# ATmega328PB register map
Vendor: Atmel; File version: 1.0
CPU: other r0p0, little endian, no MPU, no FPU, 4 interrupt priority bits
Registers are 8-bit, read-write, reset 0x0 unless marked. A register's access mark holds for its fields unless they carry their own. Offsets are from the block's base; [hi:lo] are bit positions; {n}, {i} and the like mark numbered series; 'fields as' and 'values as' point back to an identical list.

## EXINT
Base 0x0000003B
0x00 PCIFR — Pin Change Interrupt Flag Register
  [3:0] PCIF — Pin Change Interrupt Flags
0x01 EIFR — External Interrupt Flag Register
  [1:0] INTF — External Interrupt Flags
0x02 EIMSK — External Interrupt Mask Register
  [1:0] INT — External Interrupt Request 1 Enable
0x2D PCICR — Pin Change Interrupt Control Register
  [3:0] PCIE — Pin Change Interrupt Enables
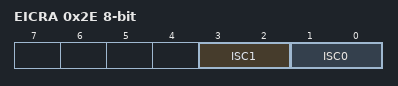
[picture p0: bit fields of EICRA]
0x2E EICRA — External Interrupt Control Register
  [3:2] ISC1 — External Interrupt Sense Control 1 Bits
    0=LOW_LEVEL_OF_INTX; 1=ANY_LOGICAL_CHANGE_OF_INTX; 2=FALLING_EDGE_OF_INTX; 3=RISING_EDGE_OF_INTX
  [1:0] ISC0 — External Interrupt Sense Control 0 Bits
    values as ISC1
0x30 PCMSK0 — Pin Change Mask Register 0
  [7:0] PCINT — Pin Change Enable Masks
0x31 PCMSK1 — Pin Change Mask Register 1
  [6:0] PCINT — Pin Change Enable Masks
0x32 PCMSK2 — Pin Change Mask Register 2
  [7:0] PCINT — Pin Change Enable Masks
0x38 PCMSK3 — Pin Change Mask Register 3
  [3:0] PCINT — Pin Change Enable Masks

## LOCKBIT — Lockbits
Base 0x00000000
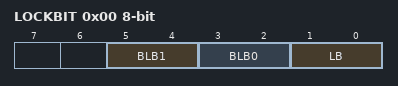
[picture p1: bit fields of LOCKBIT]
0x00 LOCKBIT
  [5:4] BLB1 — Boot Loader Protection Mode
    0=LPM_SPM_DISABLE (LPM and SPM prohibited in Boot Section); 1=LPM_DISABLE (LPM prohibited in Boot Section); 2=SPM_DISABLE (SPM prohibited in Boot Section); 3=NO_LOCK (No lock on SPM and LPM in Boot Section)
  [3:2] BLB0 — Boot Loader Protection Mode
    0=LPM_SPM_DISABLE (LPM and SPM prohibited in Application Section); 1=LPM_DISABLE (LPM prohibited in Application Section); 2=SPM_DISABLE (SPM prohibited in Application Section); 3=NO_LOCK (No lock on SPM and LPM in Application Section)
  [1:0] LB — Memory Lock
    0=PROG_VER_DISABLED (Further programming and verification disabled); 2=PROG_DISABLED (Further programming disabled); 3=NO_LOCK (No memory lock features enabled)

## PORTB — I/O Port
Base 0x00000023
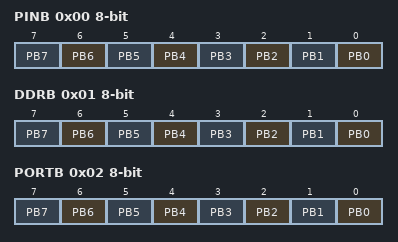
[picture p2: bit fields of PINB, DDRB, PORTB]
0x00 PINB — Port B Input Pins
  [n] PB{n} (n=0..7) — Pin B{n}
0x01 DDRB — Port B Data Direction Register
  [n] PB{n} (n=0..7) — Pin B{n}
0x02 PORTB — Port B Data Register
  [n] PB{n} (n=0..7) — Pin B{n}

## PORTC — I/O Port
Base 0x00000026
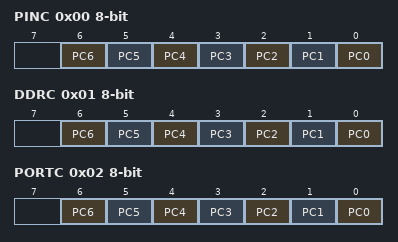
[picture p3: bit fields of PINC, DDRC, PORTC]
0x00 PINC — Port C Input Pins
  [n] PC{n} (n=0..6) — Pin C{n}
0x01 DDRC — Port C Data Direction Register
  [n] PC{n} (n=0..6) — Pin C{n}
0x02 PORTC — Port C Data Register
  [n] PC{n} (n=0..6) — Pin C{n}

## PORTD — I/O Port
Base 0x00000029
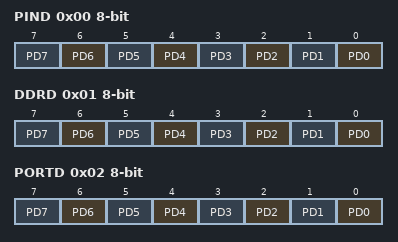
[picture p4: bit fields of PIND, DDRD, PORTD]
0x00 PIND — Port D Input Pins
  [n] PD{n} (n=0..7) — Pin D{n}
0x01 DDRD — Port D Data Direction Register
  [n] PD{n} (n=0..7) — Pin D{n}
0x02 PORTD — Port D Data Register
  [n] PD{n} (n=0..7) — Pin D{n}

## PORTE — I/O Port
Base 0x0000002C
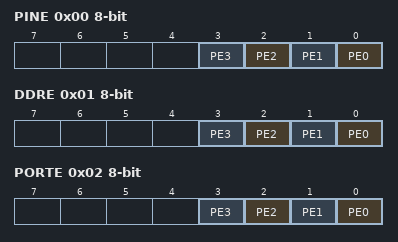
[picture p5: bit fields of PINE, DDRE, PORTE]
0x00 PINE — Port E Input Pins
  [n] PE{n} (n=0..3) — Pin E{n}
0x01 DDRE — Port E Data Direction Register
  [n] PE{n} (n=0..3) — Pin E{n}
0x02 PORTE — Port E Data Register
  [n] PE{n} (n=0..3) — Pin E{n}

## SPI0
Base 0x0000004C
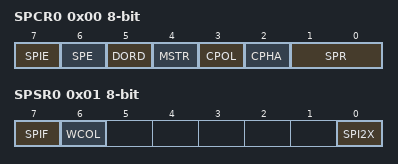
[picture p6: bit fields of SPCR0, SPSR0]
0x00 SPCR0 — SPI Control Register
  [7] SPIE — SPI Interrupt Enable
  [6] SPE — SPI Enable
  [5] DORD — Data Order
  [4] MSTR — Master/Slave Select
  [3] CPOL — Clock polarity
  [2] CPHA — Clock Phase
  [1:0] SPR — SPI Clock Rate Selects
    0=FOSC_2_OR_FOSC_4; 1=FOSC_8_OR_FOSC_16; 2=FOSC_32_OR_FOSC_64; 3=FOSC_64_OR_FOSC_128
0x01 SPSR0 — SPI Status Register
  [7] SPIF — SPI Interrupt Flag
  [6] WCOL — Write Collision Flag
  [0] SPI2X — Double SPI Speed Bit
0x02 SPDR0 — SPI Data Register

## SPI1
Base 0x000000AC
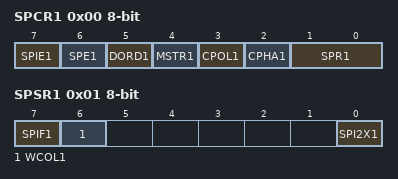
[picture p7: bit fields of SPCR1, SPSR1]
0x00 SPCR1 — SPI Control Register
  [7] SPIE1 — SPI Interrupt Enable
  [6] SPE1 — SPI Enable
  [5] DORD1 — Data Order
  [4] MSTR1 — Master/Slave Select
  [3] CPOL1 — Clock polarity
  [2] CPHA1 — Clock Phase
  [1:0] SPR1 — SPI Clock Rate Selects
    0=FOSC_2_OR_FOSC_4; 1=FOSC_8_OR_FOSC_16; 2=FOSC_32_OR_FOSC_64; 3=FOSC_64_OR_FOSC_128
0x01 SPSR1 — SPI Status Register
  [7] SPIF1 — SPI Interrupt Flag
  [6] WCOL1 — Write Collision Flag
  [0] SPI2X1 — Double SPI Speed Bit
0x02 SPDR1 — SPI Data Register
